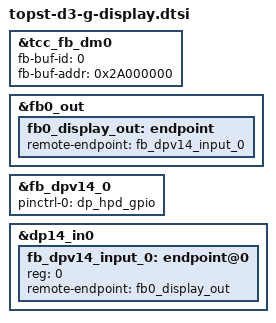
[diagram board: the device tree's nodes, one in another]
// SPDX-License-Identifier: (GPL-2.0-or-later OR MIT)
/*
 * Copyright (C) 2023 Telechips Inc.
 */

#define DP_HPD_GPIO "gpc-14"
#include "topst-d3-g-disp-target-config.dtsi"
#include "tcc805x-disp.dtsi"
/*==============================================================================
 * TCC805x DISPLAY PATH (Single output for U-Boot console)
 * ---------------------------
 * FB0 : fb0<fb0_display_out> -> <fb_dpv14_input_0>fb_dpv14_0
 *       RDMA0 - WMIX0 - DISP0 -> MUX3 -> DP0 (MAIN)
 *
 * Only FB0->DP0 is enabled. With all 4 enabled, tcc_dpv14_enable()
 * waits for num_of_dps=4 enable calls, but U-Boot only probes one
 * video device for the console, so dpv14_enable() never fires.
==============================================================================*/

/* FB0 only */
&tcc_fb_dm0 {
	status = "okay";
	fb-buf-id = <0>;
	fb-buf-addr = <0x2A000000>;
};

/* FB0: fb0_display_out -> DP0: fb_dpv14_input_0 */
&fb0_out {
	fb0_display_out: endpoint {
		remote-endpoint = <&fb_dpv14_input_0>;
	};
};

/* DP0 only */
&fb_dpv14_0 {
	status = "okay";
	pinctrl-0 = <&dp_hpd_gpio>;
};

/* FB0: fb0_display_out -> DP0: fb_dpv14_input_0 */
&dp14_in0 {
	fb_dpv14_input_0: endpoint@0 {
		reg = <0>;
		remote-endpoint = <&fb0_display_out>;
	};
};
